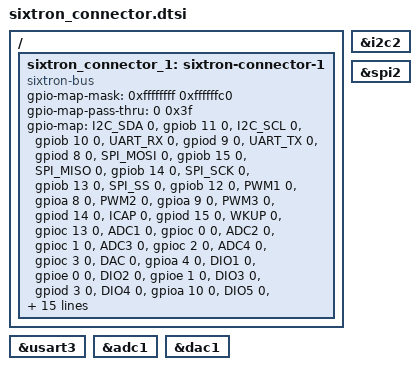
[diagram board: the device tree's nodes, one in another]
/*
 * Copyright (c) 2024 CATIE
 * SPDX-License-Identifier: Apache-2.0
 */

#include <zephyr/dt-bindings/gpio/sixtron-header.h>

/ {
    sixtron_connector_1: sixtron-connector-1 {
        compatible = "sixtron-bus";
        #gpio-cells = <2>;
        gpio-map-mask = <0xffffffff 0xffffffc0>;
        gpio-map-pass-thru = <0 0x3f>;
        gpio-map = <I2C_SDA 0 &gpiob 11 0>,
                   <I2C_SCL 0 &gpiob 10 0>,
                   <UART_RX 0 &gpiod 9 0>,
                   <UART_TX 0 &gpiod 8 0>,
                   <SPI_MOSI 0 &gpiob 15 0>,
                   <SPI_MISO 0 &gpiob 14 0>,
                   <SPI_SCK 0 &gpiob 13 0>,
                   <SPI_SS 0 &gpiob 12 0>,
                   <PWM1 0 &gpioa 8 0>,
                   <PWM2 0 &gpioa 9 0>,
                   <PWM3 0 &gpiod 14 0>,
                   <ICAP 0 &gpiod 15 0>,
                   <WKUP 0 &gpioc 13 0>,
                   <ADC1 0 &gpioc 0 0>,
                   <ADC2 0 &gpioc 1 0>,
                   <ADC3 0 &gpioc 2 0>,
                   <ADC4 0 &gpioc 3 0>,
                   <DAC 0 &gpioa 4 0>,
                   <DIO1 0 &gpioe 0 0>,
                   <DIO2 0 &gpioe 1 0>,
                   <DIO3 0 &gpiod 3 0>,
                   <DIO4 0 &gpioa 10 0>,
                   <DIO5 0 &gpiod 10 0>,
                   <DIO6 0 &gpioa 7 0>,
                   <DIO7 0 &gpioa 6 0>,
                   <DIO8 0 &gpioa 5 0>,
                   <DIO9 0 &gpioe 8 0>,
                   <DIO10 0 &gpioe 7 0>,
                   <DIO11 0 &gpiob 8 0>,
                   <DIO12 0 &gpiob 7 0>,
                   <DIO13 0 &gpioc 2 0>,
                   <DIO14 0 &gpiod 2 0>,
                   <DIO15 0 &gpioc 7 0>,
                   <DIO16 0 &gpioc 6 0>,
                   <DIO17 0 &gpiob 9 0>,
                   <DIO18 0 &gpiob 6 0>,
                   <DIO19 0 &gpioc 11 0>,
                   <DIO20 0 &gpioc 10 0>
                   <DIO21 0 &gpioc 9 0>,
                   <DIO22 0 &gpioc 8 0>
                   <DIO25 0 &gpioe 12 0>,
                   <DIO26 0 &gpioe 13 0>,
                   <DIO27 0 &gpioe 14 0>,
                   <DIO28 0 &gpioe 15 0>,
                   <DIO29 0 &gpiod 4 0>,
                   <DIO30 0 &gpiod 5 0>,
                   <DIO31 0 &gpiod 6 0>,
                   <DIO32 0 &gpiod 7 0>,
                   <DIO33 0 &gpiob 2 0>,
                   <DIO34 0 &gpioe 11 0>,
                   <DIO35 0 &gpioe 10 0>,
                   <DIO36 0 &gpioe 9 0>;
    };
};

sixtron_connector_1_i2c: &i2c2 {};
sixtron_connector_1_uart: &usart3 {};
sixtron_connector_1_spi: &spi2 {};
sixtron_connector_1_adc: &adc1 {};
sixtron_connector_1_dac: &dac1 {};

sixtron_i2c: &sixtron_connector_1_i2c {};
sixtron_uart: &sixtron_connector_1_uart {};
sixtron_spi: &sixtron_connector_1_spi {};
sixtron_adc: &sixtron_connector_1_adc {};
sixtron_dac: &sixtron_connector_1_dac {};
